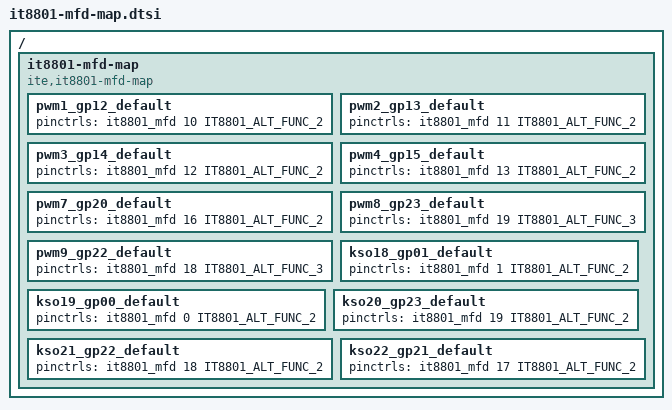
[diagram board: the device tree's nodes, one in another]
/*
 * Copyright (c) 2024 ITE Corporation. All Rights Reserved.
 *
 * SPDX-License-Identifier: Apache-2.0
 */

#include <zephyr/dt-bindings/mfd/mfd_it8801_altctrl.h>

/ {
	/* GPIO pin mapping to alternate function */
	it8801-mfd-map {
		compatible = "ite,it8801-mfd-map";

		/* PWM alternate function */
		pwm1_gp12_default: pwm1_gp12_default {
			pinctrls = <&it8801_mfd 10 IT8801_ALT_FUNC_2>;
		};

		pwm2_gp13_default: pwm2_gp13_default {
			pinctrls = <&it8801_mfd 11 IT8801_ALT_FUNC_2>;
		};

		pwm3_gp14_default: pwm3_gp14_default {
			pinctrls = <&it8801_mfd 12 IT8801_ALT_FUNC_2>;
		};

		pwm4_gp15_default: pwm4_gp15_default {
			pinctrls = <&it8801_mfd 13 IT8801_ALT_FUNC_2>;
		};

		pwm7_gp20_default: pwm7_gp20_default {
			pinctrls = <&it8801_mfd 16 IT8801_ALT_FUNC_2>;
		};

		pwm8_gp23_default: pwm8_gp23_default {
			pinctrls = <&it8801_mfd 19 IT8801_ALT_FUNC_3>;
		};

		pwm9_gp22_default: pwm9_gp22_default {
			pinctrls = <&it8801_mfd 18 IT8801_ALT_FUNC_3>;
		};

		/* Keyboard alternate function */
		kso18_gp01_default: kso18_gp01_default {
			pinctrls = <&it8801_mfd 1 IT8801_ALT_FUNC_2>;
		};

		kso19_gp00_default: kso19_gp00_default {
			pinctrls = <&it8801_mfd 0 IT8801_ALT_FUNC_2>;
		};

		kso20_gp23_default: kso20_gp23_default {
			pinctrls = <&it8801_mfd 19 IT8801_ALT_FUNC_2>;
		};

		kso21_gp22_default: kso21_gp22_default {
			pinctrls = <&it8801_mfd 18 IT8801_ALT_FUNC_2>;
		};

		kso22_gp21_default: kso22_gp21_default {
			pinctrls = <&it8801_mfd 17 IT8801_ALT_FUNC_2>;
		};
	};
};
